AUTOSAR XML (schema 3.2.1)
package /SYSTEM
  system New_Element_6080: fibex-element=[F_STD_0x200, REF_ECU, AUT, MONonCAN_Endurance_V321, F_STD_0x200_S1, F_STD_0x200_S2, F_STD_0x200_S3, F_STD_0x200_S4, F_STD_0x200_S5, F_STD_0x200_S6, F_STD_0x200_S7, F_STD_0x200_S8, F_STD_0x200_S12, F_STD_0x200_S16, F_STD_0x200_PDU]
package /MONonCAN_Endurance_V321
  can cluster MONonCAN_Endurance_V321: max-frame-length=8, nm-node-detection-enabled=false, nm-node-id-enabled=false, nm-repeat-message-support=false, protocol-name=CAN, speed=1000000
    physical channel CANChannel
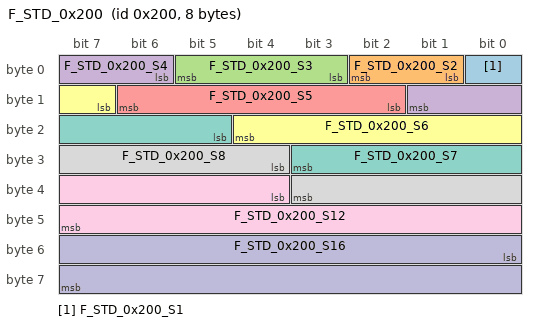
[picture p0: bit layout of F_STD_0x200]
      frame F_STD_0x200: id 0x200, from REF_ECU, to AUT, frame-length=8, can-addressing-mode=STANDARD
        pdu F_STD_0x200_PDU: length=64
          signal F_STD_0x200_S1: start 0, 1 bit, little-endian, to AUT
          signal F_STD_0x200_S2: start 1, 2 bit, little-endian, to AUT
          signal F_STD_0x200_S3: start 3, 3 bit, little-endian, to AUT
          signal F_STD_0x200_S4: start 6, 4 bit, little-endian, to AUT
          signal F_STD_0x200_S5: start 10, 5 bit, little-endian, to AUT
          signal F_STD_0x200_S6: start 15, 6 bit, little-endian, to AUT
          signal F_STD_0x200_S7: start 21, 7 bit, little-endian, to AUT
          signal F_STD_0x200_S8: start 28, 8 bit, little-endian, to AUT
          signal F_STD_0x200_S12: start 36, 12 bit, little-endian, to AUT
          signal F_STD_0x200_S16: start 48, 16 bit, little-endian, to AUT
package /ECU_INSTANCES
  ecu instance REF_ECU: diagnostic-address=0, sleep-mode-supported=false, wake-up-over-bus-supported=false
    can communication controller Controller_REF_ECU: wake-up-by-controller-supported=false
    can communication connector Connector_REF_ECU: channel=CANChannel, comm-controller=Controller_REF_ECU
  ecu instance AUT: diagnostic-address=0, sleep-mode-supported=false, wake-up-over-bus-supported=false
    can communication controller Controller_AUT: wake-up-by-controller-supported=false
    can communication connector Connector_AUT: channel=CANChannel, comm-controller=Controller_AUT
